# NUC029AN_v1 register map
File version: 1.0
Registers are 32-bit, read-write, reset 0x0 unless marked. A register's access mark holds for its fields unless they carry their own. Offsets are from the block's base; [hi:lo] are bit positions.

## WDT — WDT Register Map
Base 0x40004000
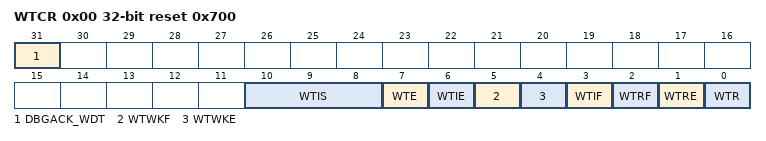
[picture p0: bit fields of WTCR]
0x00 WTCR reset 0x700 — Watchdog Timer Control Register
  [31] DBGACK_WDT — ICE debug mode acknowledge Disable (write-protected). Watchdog Timer counter will keep going no matter ICE debug mode acknowledged or not.
    0=ICE debug mode acknowledgement effects Watchdog Timer counting; 1=ICE debug mode acknowledgement disabled
  [10:8] WTIS — Watchdog Timer Interval Select (write protection bits)
  [7] WTE — Watchdog Timer Enable (write protection bits)
    0=Disable the Watchdog timer (This action will reset the internal counter); 1=Enable the Watchdog timer
  [6] WTIE — Watchdog Timer Interrupt Enable (write protection bits)
    0=Disable the Watchdog timer interrupt; 1=Enable the Watchdog timer interrupt
  [5] WTWKF — Watchdog Timer Wake-up Flag. If Watchdog timer causes chip wakes up from power down mode, this bit will be set to high. It must be cleared by software with a write 1 to this bit.
    0=Watchdog timer does not cause chip wake-up; 1=Chip wake-up from idle or power down mode by Watchdog timeout
  [4] WTWKE — Watchdog Timer Wake-up Function Enable bit (write-protection bit). Note: Chip can wake-up by WDT only if WDT clock source select RC10K
    0=Disable Watchdog timer wake-up chip function; 1=Enable the Wake-up function that Watchdog timer timeout can wake-up chip from power down mode
  [3] WTIF — Watchdog Timer Interrupt Flag. When watchdog timeout, the hardware will set this bit to indicate that the Watchdog timer interrupt has occurred. Note: This bit is cleared by writing 1 to this bit.
    0=Watchdog timer interrupt did not occur; 1=Watchdog timer interrupt occurs
  [2] WTRF — Watchdog Timer Reset Flag. When the Watchdog timer initiates a reset, the hardware will set this bit. This flag can be read by software to determine the source of reset. Software is responsible to clear it manually by writing 1 to it. If WTRE is disabled, then the Watchdog timer has no effect on this bit. Note: Write 1 to clear this bit to zero.
    0=Watchdog timer reset did not occur; 1=Watchdog timer reset occurs
  [1] WTRE — Watchdog Timer Reset Enable. Setting this bit will enable the Watchdog timer reset function.
    0=Disable Watchdog timer reset function; 1=Enable Watchdog timer reset function
  [0] WTR — Clear Watchdog Timer (write-protection bit). Set this bit will clear the Watchdog timer. Note: This bit will be auto cleared by hardware
    0=Writing 0 to this bit has no effect; 1=Reset the contents of the Watchdog timer
0x04 WTCRALT — Watchdog Timer Alternative Control Register
  [1:0] WTRDSEL — Watchdog Timer Reset Delay Select (Write-protection Bits). When WDT time-out happened, software has a time named WDT reset delay period to clear WDT counter to prevent WDT time-out reset happened. Software can select a suitable value of WDT reset delay period for different WDT time-out period. These bits are protected bit. It means programming this bit needs to write "59h", "16h", "88h" to address 0x5000_0100 to disable register protection. Reference the register REGWRPROT at address GCR_BA+0x100. This register will be reset to 0 if WDT time-out reset happened
    0=Watchdog Timer reset delay period is (1024+2) * WDT_CLK; 1=Watchdog Timer reset delay period is (128+2) * WDT_CLK; 2=Watchdog Timer reset delay period is (16+2) * WDT_CLK; 3=Watchdog Timer reset delay period is (1+2) * WDT_CLK

## WWDT — WWDT Register Map
Base 0x40004100
0x00 WWDTRLD wo — Window Watchdog Timer Reload Counter Register
  [31:0] WWDTRLD — WWDT Reload Counter Register. Writing 0x00005AA5 to this register will reload the Window Watchdog Timer counter value to 0x3F. Note: Software can only write WWDTRLD to reload WWDT counter value when current WWDT counter value between 0 and WINCMP. If software writes WWDTRLD when current WWDT counter value larger than WINCMP, WWDT reset signal will generate immediately.
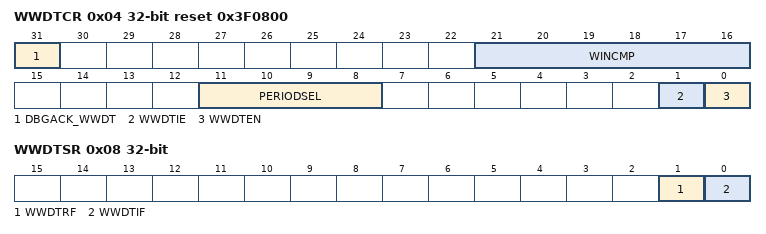
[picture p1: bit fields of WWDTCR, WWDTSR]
0x04 WWDTCR reset 0x3F0800 — Window Watchdog Timer Control Register
  [31] DBGACK_WWDT — ICE debug mode acknowledge Disable
    0=WWDT counter stopped if system is in Debug mode; 1=WWDT still counted even system is in Debug mode
  [21:16] WINCMP — WWDT Window Compare Register. Set this register to adjust the valid reload window. Note: Software can only write WWDTRLD to reload WWDT counter value when current WWDT counter value between 0 and WINCMP. If Software writes WWDTRLD when current WWDT counter value larger than WINCMP, WWDT reset signal will generate immediately.
  [11:8] PERIODSEL — WWDT Pre-scale Period Select
  [1] WWDTIE — WWDT Interrupt Enable. Setting this bit to enable the Window Watchdog Timer time-out interrupt function.
    0=WWDT time-out interrupt function Disabled if WWDTIF (WWDTSR[0] WWDT compare match interrupt flag) is 1; 1=WWDT time-out interrupt function Enabled if WWDTIF (WWDTSR[0] WWDT compare match interrupt flag) is 1
  [0] WWDTEN — WWDT Enable. Set this bit to enable Window Watchdog Timer counter counting.
    0=Window Watchdog Timer counter is stopped; 1=Window Watchdog Timer counter is starting counting
0x08 WWDTSR — Window Watchdog Timer Status Register
  [1] WWDTRF — WWDT Reset Flag. When WWDT counter counts down to 0 or writes WWDTRLD during current WWDT counter value larger than WINCMP, chip will be reset and this bit is set to 1. This bit will be cleared to 0 by writing 1 to itself.
  [0] WWDTIF — WWDT Compare Match Interrupt Flag. When current WWDT counter value matches to WWCMP, this bit is set to 1. This bit will be cleared by writing 1 to itself.
0x0C WWDTCVR ro reset 0x3F — Window Watchdog Timer Counter Value Register
  [5:0] WWDTCVAL — WWDT Counter Value. This register reflects the current WWDT counter value and this register is read only
